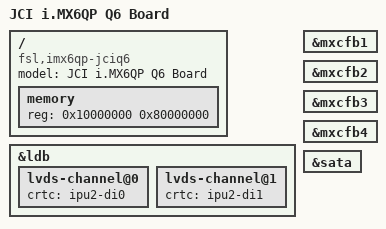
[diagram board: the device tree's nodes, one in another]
/*
 * Copyright 2012=2015 Freescale Semiconductor, Inc.
 * Copyright 2011 Linaro Ltd.
 *
 * The code contained herein is licensed under the GNU General Public
 * License. You may obtain a copy of the GNU General Public License
 * Version 2 or later at the following locations:
 *
 * http://www.opensource.org/licenses/gpl-license.html
 * http://www.gnu.org/copyleft/gpl.html
 */

/dts-v1/;

// includes non-QP .dts
#include "imx6q-jciq6.dts"
#include "imx6qp.dtsi"

/ {
	model = "JCI i.MX6QP Q6 Board";
	compatible = "fsl,imx6qp-jciq6", "fsl,imx6q";

	memory {
		reg = <0x10000000 0x80000000>;	/* reg = 0x10000000 base addr, 0x80000000 size = 2GB */
	};
};

&ldb {
	lvds-channel@0 {
		crtc = "ipu2-di0";
	};

	lvds-channel@1 {
		crtc = "ipu2-di1";
	};
};

&mxcfb1 {
	status = "okay";
};

&mxcfb2 {
	status = "okay";
};

&mxcfb3 {
	status = "okay";
};

&mxcfb4 {
	status = "okay";
};

&sata {
	status = "okay";
};

